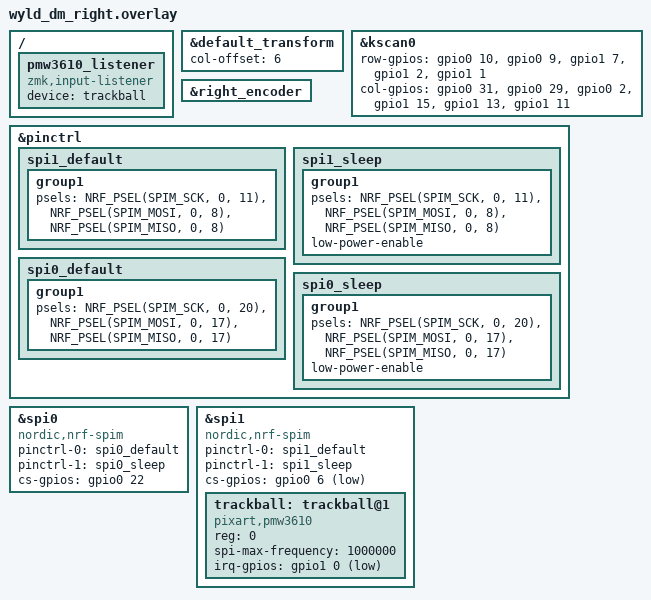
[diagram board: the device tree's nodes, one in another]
// wyld_dm_right.overlay

#include "wyld_dm.dtsi"
#include <dt-bindings/led/led.h>

&default_transform {
    col-offset = <6>;
};


///  NANO V2 PINS

&kscan0 {
   row-gpios
			= <&gpio0 10 (GPIO_ACTIVE_HIGH | GPIO_PULL_DOWN)>  // 0.10
		    , <&gpio0 9 (GPIO_ACTIVE_HIGH | GPIO_PULL_DOWN)>  // 0.9
            , <&gpio1 7 (GPIO_ACTIVE_HIGH | GPIO_PULL_DOWN)>  // 1.07
			, <&gpio1 2 (GPIO_ACTIVE_HIGH | GPIO_PULL_DOWN)>  // 1.02
			, <&gpio1 1 (GPIO_ACTIVE_HIGH | GPIO_PULL_DOWN)>  // 1.03
            ;
    col-gpios
			= <&gpio0 31  GPIO_ACTIVE_HIGH>  // 0.31
			, <&gpio0 29  GPIO_ACTIVE_HIGH>  // 0.29
            , <&gpio0 2  GPIO_ACTIVE_HIGH>  // 0.02
			, <&gpio1 15  GPIO_ACTIVE_HIGH>  //  1.15
			, <&gpio1 13  GPIO_ACTIVE_HIGH>  // 1.13
			, <&gpio1 11  GPIO_ACTIVE_HIGH>  //  1.0
//            , <&gpio1 04 GPIO_ACTIVE_HIGH>  // PB13   / 1.04
			;
};

&right_encoder {
	status = "okay";
};

&pinctrl {
    spi1_default: spi1_default {
        group1 {
            psels = <NRF_PSEL(SPIM_SCK, 0, 11)>,
                <NRF_PSEL(SPIM_MOSI, 0, 8)>,
			    <NRF_PSEL(SPIM_MISO, 0, 8)>;
        };
    };
    spi1_sleep: spi1_sleep {
        group1 {
            psels = <NRF_PSEL(SPIM_SCK, 0, 11)>,
                <NRF_PSEL(SPIM_MOSI, 0, 8)>,
			    <NRF_PSEL(SPIM_MISO, 0, 8)>;
            low-power-enable;
        };
    };

    spi0_default: spi0_default {
        group1 {
            psels = <NRF_PSEL(SPIM_SCK, 0, 20)>,
                <NRF_PSEL(SPIM_MOSI, 0, 17)>,
                <NRF_PSEL(SPIM_MISO, 0, 17)>;
        };
    };
    spi0_sleep: spi0_sleep {
        group1 {
            psels = <NRF_PSEL(SPIM_SCK, 0, 20)>,
                <NRF_PSEL(SPIM_MOSI, 0, 17)>,
                <NRF_PSEL(SPIM_MISO, 0, 17)>;
            low-power-enable;
        };
    };
};

nice_view_spi: &spi0 {
    compatible = "nordic,nrf-spim";
    pinctrl-0 = <&spi0_default>;
    pinctrl-1 = <&spi0_sleep>;
    pinctrl-names = "default", "sleep";
    cs-gpios = <&gpio0 22 GPIO_ACTIVE_HIGH>;
};

&spi1 {
compatible = "nordic,nrf-spim";
  status = "okay";

  pinctrl-0 = <&spi1_default>;
  pinctrl-1 = <&spi1_sleep>;
  pinctrl-names = "default", "sleep";
  cs-gpios = <&gpio0 6 GPIO_ACTIVE_LOW>;
  trackball: trackball@1 {
      status = "okay";
      compatible = "pixart,pmw3610";
      reg = <0>;
      spi-max-frequency = <1000000>;
      irq-gpios = <&gpio1 0 (GPIO_ACTIVE_LOW | GPIO_PULL_UP)>;
//      snipe-layers = <1>;
//      scroll-layers = <2>;
//      automouse-layer = <3>;
  };
};


/ {
  pmw3610_listener {
    compatible = "zmk,input-listener";
    device = <&trackball>;
  };
};


